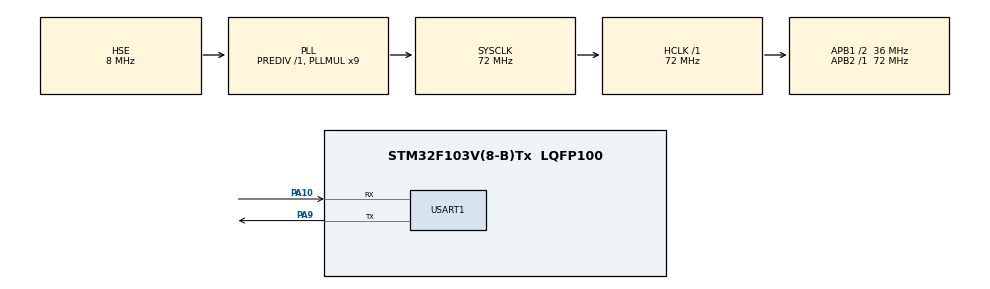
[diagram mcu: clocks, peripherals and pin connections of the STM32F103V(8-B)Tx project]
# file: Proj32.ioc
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Dma.Request0=USART1_RX
Dma.Request1=USART1_TX
Dma.USART1_RX.0.Direction=DMA_PERIPH_TO_MEMORY
Dma.USART1_RX.0.Instance=DMA1_Channel5
Dma.USART1_RX.0.MemDataAlignment=DMA_MDATAALIGN_BYTE
Dma.USART1_RX.0.MemInc=DMA_MINC_ENABLE
Dma.USART1_RX.0.Mode=DMA_NORMAL
Dma.USART1_RX.0.PeriphDataAlignment=DMA_PDATAALIGN_BYTE
Dma.USART1_RX.0.PeriphInc=DMA_PINC_DISABLE
Dma.USART1_RX.0.Priority=DMA_PRIORITY_LOW
Dma.USART1_TX.1.Direction=DMA_MEMORY_TO_PERIPH
Dma.USART1_TX.1.Instance=DMA1_Channel4
Dma.USART1_TX.1.MemDataAlignment=DMA_MDATAALIGN_BYTE
Dma.USART1_TX.1.MemInc=DMA_MINC_ENABLE
Dma.USART1_TX.1.Mode=DMA_NORMAL
Dma.USART1_TX.1.PeriphDataAlignment=DMA_PDATAALIGN_BYTE
Dma.USART1_TX.1.PeriphInc=DMA_PINC_DISABLE
Dma.USART1_TX.1.Priority=DMA_PRIORITY_LOW
Mcu.Family=STM32F1
Mcu.Name=STM32F103V(8-B)Tx
Mcu.Package=LQFP100
NVIC.DMA1_Channel4_IRQn=true\:0\:0\:false\:false\:true\:false\:true
NVIC.DMA1_Channel5_IRQn=true\:0\:0\:false\:false\:true\:false\:true
NVIC.PriorityGroup=NVIC_PRIORITYGROUP_4
NVIC.USART1_IRQn=true\:0\:0\:false\:false\:true\:true\:true
OSC_IN.Mode=HSE-External-Oscillator
OSC_IN.Signal=RCC_OSC_IN
OSC_OUT.Mode=HSE-External-Oscillator
OSC_OUT.Signal=RCC_OSC_OUT
PA10.Mode=Asynchronous
PA10.Signal=USART1_RX
PA13.Mode=Serial_Wire
PA13.Signal=SYS_JTMS-SWDIO
PA14.Mode=Serial_Wire
PA14.Signal=SYS_JTCK-SWCLK
PA9.Mode=Asynchronous
PA9.Signal=USART1_TX
ProjectManager.HeapSize=0x200
ProjectManager.StackSize=0x400
ProjectManager.TargetToolchain=STM32CubeIDE
RCC.AHBFreq_Value=72000000
RCC.APB1CLKDivider=RCC_HCLK_DIV2
RCC.APB1Freq_Value=36000000
RCC.APB1TimFreq_Value=72000000
RCC.APB2Freq_Value=72000000
RCC.APB2TimFreq_Value=72000000
RCC.HCLKFreq_Value=72000000
RCC.PLLMUL=RCC_PLL_MUL9
RCC.PLLSourceVirtual=RCC_PLLSOURCE_HSE
RCC.SYSCLKFreq_VALUE=72000000
RCC.SYSCLKSource=RCC_SYSCLKSOURCE_PLLCLK
RCC.USBFreq_Value=72000000
USART1.VirtualMode=VM_ASYNC
board=custom

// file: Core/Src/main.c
/* USER CODE BEGIN Header */
/**
  ******************************************************************************
  * @file           : main.c
  * @brief          : Main program body
  ******************************************************************************
  * @attention
  *
  * Copyright (c) 2021 STMicroelectronics.
  * All rights reserved.
  *
  * This software is licensed under terms that can be found in the LICENSE file
  * in the root directory of this software component.
  * If no LICENSE file comes with this software, it is provided AS-IS.
  *
  ******************************************************************************
  */
/* USER CODE END Header */
#include "main.h"

/* USER CODE BEGIN Includes */
#include "stdio.h"
#include "stdarg.h"
#include "stm32f1xx_hal_uart.h"

/* USER CODE END Includes */

/* USER CODE BEGIN PTD */
uint8_t rx_buff[Buff_Size] = "hell0,uart DMA\r\n";
uint8_t rx_done = 0; //接收完成标志
uint8_t rx_cnt = 0;//接收数据长度
/* USER CODE END PTD */

UART_HandleTypeDef huart1;
DMA_HandleTypeDef hdma_usart1_rx;
DMA_HandleTypeDef hdma_usart1_tx;

void SystemClock_Config(void);
static void MX_GPIO_Init(void);
static void MX_DMA_Init(void);
static void MX_USART1_UART_Init(void);
/* USER CODE BEGIN PFP */
void printf_DMA(const char *format,...);
/* USER CODE END PFP */

int main(void)
{

  /* MCU Configuration--------------------------------------------------------*/

  /* Reset of all peripherals, Initializes the Flash interface and the Systick. */
  HAL_Init();

  /* Configure the system clock */
  SystemClock_Config();

  /* Initialize all configured peripherals */
  MX_GPIO_Init();
  MX_DMA_Init();
  MX_USART1_UART_Init();

  /* Infinite loop */
  /* USER CODE BEGIN WHILE */
    HAL_UART_Transmit_DMA(&huart1, (uint8_t *)rx_buff, sizeof(rx_buff));
    HAL_Delay(1000);

    printf_DMA("DMA UART Printf test!\r\n");

    while (1)
    {
        /* USER CODE END WHILE */

        if(rx_done == 1)//判读是否接收完成
        {
            rx_done = 0;//清除接收标志
            //数据处理，打印接收长度、接收的数据
            printf_DMA("length of rx data: %d!\r\n",rx_cnt);
            for(int i = 0;i<rx_cnt;i++) printf_DMA("%c",rx_buff[i]);
            printf_DMA("\r\n");

            rx_cnt =0;//清除接收长度
        }
    }
}

void SystemClock_Config(void)
{
  RCC_OscInitTypeDef RCC_OscInitStruct = {0};
  RCC_ClkInitTypeDef RCC_ClkInitStruct = {0};

  /** Initializes the RCC Oscillators according to the specified parameters
  * in the RCC_OscInitTypeDef structure.
  */
  RCC_OscInitStruct.OscillatorType = RCC_OSCILLATORTYPE_HSE;
  RCC_OscInitStruct.HSEState = RCC_HSE_ON;
  RCC_OscInitStruct.HSEPredivValue = RCC_HSE_PREDIV_DIV1;
  RCC_OscInitStruct.HSIState = RCC_HSI_ON;
  RCC_OscInitStruct.PLL.PLLState = RCC_PLL_ON;
  RCC_OscInitStruct.PLL.PLLSource = RCC_PLLSOURCE_HSE;
  RCC_OscInitStruct.PLL.PLLMUL = RCC_PLL_MUL9;
  if (HAL_RCC_OscConfig(&RCC_OscInitStruct) != HAL_OK)
  {
    Error_Handler();
  }
  /** Initializes the CPU, AHB and APB buses clocks
  */
  RCC_ClkInitStruct.ClockType = RCC_CLOCKTYPE_HCLK|RCC_CLOCKTYPE_SYSCLK
                              |RCC_CLOCKTYPE_PCLK1|RCC_CLOCKTYPE_PCLK2;
  RCC_ClkInitStruct.SYSCLKSource = RCC_SYSCLKSOURCE_PLLCLK;
  RCC_ClkInitStruct.AHBCLKDivider = RCC_SYSCLK_DIV1;
  RCC_ClkInitStruct.APB1CLKDivider = RCC_HCLK_DIV2;
  RCC_ClkInitStruct.APB2CLKDivider = RCC_HCLK_DIV1;

  if (HAL_RCC_ClockConfig(&RCC_ClkInitStruct, FLASH_LATENCY_2) != HAL_OK)
  {
    Error_Handler();
  }
}

static void MX_USART1_UART_Init(void)
{

  huart1.Instance = USART1;
  huart1.Init.BaudRate = 115200;
  huart1.Init.WordLength = UART_WORDLENGTH_8B;
  huart1.Init.StopBits = UART_STOPBITS_1;
  huart1.Init.Parity = UART_PARITY_NONE;
  huart1.Init.Mode = UART_MODE_TX_RX;
  huart1.Init.HwFlowCtl = UART_HWCONTROL_NONE;
  huart1.Init.OverSampling = UART_OVERSAMPLING_16;
  if (HAL_UART_Init(&huart1) != HAL_OK)
  {
    Error_Handler();
  }
    /* USER CODE BEGIN USART1_Init 2 */
    //开启空闲中断
    __HAL_UART_ENABLE_IT(&huart1,UART_IT_IDLE);
    //初始化时打开DMA接收，确保第一包数据能够收到！
    HAL_UART_Receive_DMA(&huart1,rx_buff,Buff_Size);
    /* USER CODE END USART1_Init 2 */

}

static void MX_DMA_Init(void)
{

  /* DMA controller clock enable */
  __HAL_RCC_DMA1_CLK_ENABLE();

  /* DMA interrupt init */
  /* DMA1_Channel4_IRQn interrupt configuration */
  HAL_NVIC_SetPriority(DMA1_Channel4_IRQn, 0, 0);
  HAL_NVIC_EnableIRQ(DMA1_Channel4_IRQn);
  /* DMA1_Channel5_IRQn interrupt configuration */
  HAL_NVIC_SetPriority(DMA1_Channel5_IRQn, 0, 0);
  HAL_NVIC_EnableIRQ(DMA1_Channel5_IRQn);

}

static void MX_GPIO_Init(void)
{

  /* GPIO Ports Clock Enable */
  __HAL_RCC_GPIOA_CLK_ENABLE();

}

/* USER CODE BEGIN 4 */
//添加DMA串口printf函数
uint8_t _dbg_Buff[150];
void printf_DMA(const char *format,...)
{
    uint32_t length;
    va_list args;
    uint8_t  temp=0;

    va_start(args, format);
    length = vsnprintf((char*)_dbg_Buff, sizeof(_dbg_Buff)+1, (char*)format, args);
    va_end(args);

    HAL_UART_Transmit_DMA(&huart1,_dbg_Buff,length);
    //等待串口发送完成，注意是串口发送完成，不是DMA传输完成
    while(!__HAL_UART_GET_FLAG(&huart1,UART_FLAG_TC));
    //如果没有上面这条语句，连续调用printf_DMA时可能输出错误。
}
/* USER CODE END 4 */

void Error_Handler(void)
{
  __disable_irq();
  while (1)
  {
  }
}
